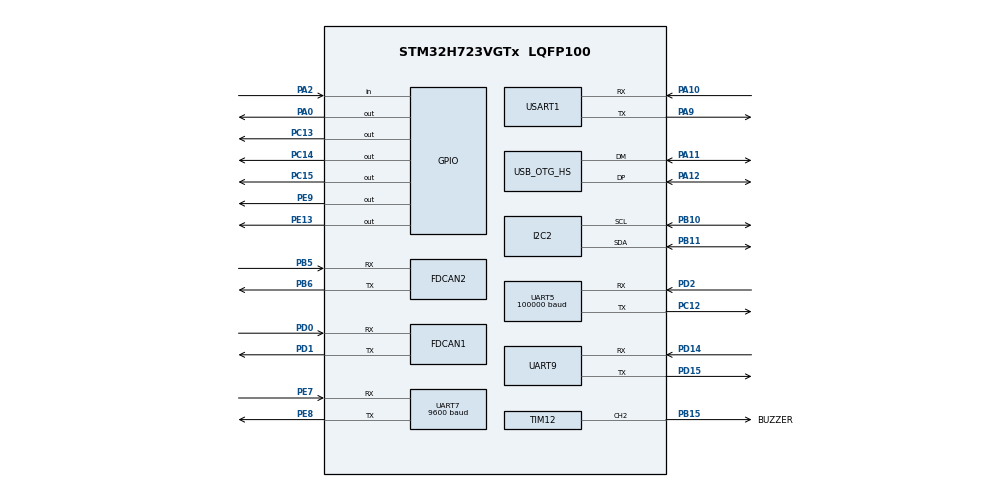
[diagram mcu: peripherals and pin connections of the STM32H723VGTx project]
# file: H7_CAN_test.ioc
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CORTEX_M7.default_mode_Activation=1
Dma.I2C2_RX.2.Direction=DMA_PERIPH_TO_MEMORY
Dma.I2C2_RX.2.EventEnable=DISABLE
Dma.I2C2_RX.2.FIFOMode=DMA_FIFOMODE_DISABLE
Dma.I2C2_RX.2.Instance=DMA1_Stream2
Dma.I2C2_RX.2.MemDataAlignment=DMA_MDATAALIGN_BYTE
Dma.I2C2_RX.2.MemInc=DMA_MINC_ENABLE
Dma.I2C2_RX.2.Mode=DMA_NORMAL
Dma.I2C2_RX.2.PeriphDataAlignment=DMA_PDATAALIGN_BYTE
Dma.I2C2_RX.2.PeriphInc=DMA_PINC_DISABLE
Dma.I2C2_RX.2.Polarity=HAL_DMAMUX_REQ_GEN_RISING
Dma.I2C2_RX.2.Priority=DMA_PRIORITY_LOW
Dma.I2C2_RX.2.RequestNumber=1
Dma.I2C2_RX.2.SignalID=NONE
Dma.I2C2_RX.2.SyncEnable=DISABLE
Dma.I2C2_RX.2.SyncPolarity=HAL_DMAMUX_SYNC_NO_EVENT
Dma.I2C2_RX.2.SyncRequestNumber=1
Dma.I2C2_RX.2.SyncSignalID=NONE
Dma.I2C2_TX.1.Direction=DMA_MEMORY_TO_PERIPH
Dma.I2C2_TX.1.EventEnable=DISABLE
Dma.I2C2_TX.1.FIFOMode=DMA_FIFOMODE_DISABLE
Dma.I2C2_TX.1.Instance=DMA1_Stream1
Dma.I2C2_TX.1.MemDataAlignment=DMA_MDATAALIGN_BYTE
Dma.I2C2_TX.1.MemInc=DMA_MINC_ENABLE
Dma.I2C2_TX.1.Mode=DMA_NORMAL
Dma.I2C2_TX.1.PeriphDataAlignment=DMA_PDATAALIGN_BYTE
Dma.I2C2_TX.1.PeriphInc=DMA_PINC_DISABLE
Dma.I2C2_TX.1.Polarity=HAL_DMAMUX_REQ_GEN_RISING
Dma.I2C2_TX.1.Priority=DMA_PRIORITY_LOW
Dma.I2C2_TX.1.RequestNumber=1
Dma.I2C2_TX.1.SignalID=NONE
Dma.I2C2_TX.1.SyncEnable=DISABLE
Dma.I2C2_TX.1.SyncPolarity=HAL_DMAMUX_SYNC_NO_EVENT
Dma.I2C2_TX.1.SyncRequestNumber=1
Dma.I2C2_TX.1.SyncSignalID=NONE
Dma.Request0=UART5_RX
Dma.Request1=I2C2_TX
Dma.Request2=I2C2_RX
Dma.UART5_RX.0.Direction=DMA_PERIPH_TO_MEMORY
Dma.UART5_RX.0.EventEnable=DISABLE
Dma.UART5_RX.0.FIFOMode=DMA_FIFOMODE_DISABLE
Dma.UART5_RX.0.Instance=DMA1_Stream0
Dma.UART5_RX.0.MemDataAlignment=DMA_MDATAALIGN_BYTE
Dma.UART5_RX.0.MemInc=DMA_MINC_ENABLE
Dma.UART5_RX.0.Mode=DMA_CIRCULAR
Dma.UART5_RX.0.PeriphDataAlignment=DMA_PDATAALIGN_BYTE
Dma.UART5_RX.0.PeriphInc=DMA_PINC_DISABLE
Dma.UART5_RX.0.Polarity=HAL_DMAMUX_REQ_GEN_RISING
Dma.UART5_RX.0.Priority=DMA_PRIORITY_LOW
Dma.UART5_RX.0.RequestNumber=1
Dma.UART5_RX.0.SignalID=NONE
Dma.UART5_RX.0.SyncEnable=DISABLE
Dma.UART5_RX.0.SyncPolarity=HAL_DMAMUX_SYNC_NO_EVENT
Dma.UART5_RX.0.SyncRequestNumber=1
Dma.UART5_RX.0.SyncSignalID=NONE
FDCAN1.CalculateBaudRateNominal=1000000
FDCAN1.CalculateTimeBitNominal=1000
FDCAN1.CalculateTimeQuantumNominal=25.0
FDCAN1.DataPrescaler=3
FDCAN1.DataSyncJumpWidth=10
FDCAN1.DataTimeSeg1=29
FDCAN1.DataTimeSeg2=10
FDCAN1.NominalPrescaler=3
FDCAN1.NominalSyncJumpWidth=10
FDCAN1.NominalTimeSeg1=29
FDCAN1.NominalTimeSeg2=10
FDCAN1.RxFifo0ElmtsNbr=2
FDCAN1.StdFiltersNbr=0x00000000
FDCAN1.TxFifoQueueElmtsNbr=2
FDCAN2.CalculateBaudRateNominal=1000000
FDCAN2.CalculateTimeBitNominal=1000
FDCAN2.CalculateTimeQuantumNominal=25.0
FDCAN2.DataPrescaler=3
FDCAN2.DataSyncJumpWidth=10
FDCAN2.DataTimeSeg1=29
FDCAN2.DataTimeSeg2=10
FDCAN2.NominalPrescaler=3
FDCAN2.NominalSyncJumpWidth=10
FDCAN2.NominalTimeSeg1=29
FDCAN2.NominalTimeSeg2=10
FDCAN2.RxFifo0ElmtsNbr=2
FDCAN2.StdFiltersNbr=0x00000000
FDCAN2.TxFifoQueueElmtsNbr=2
FREERTOS.Tasks01=defaultTask,0,128,StartDefaultTask,As weak,NULL,Dynamic,NULL,NULL;Classic_Task,0,128,Classic_Move,As weak,NULL,Dynamic,NULL,NULL;Chat_Task,0,128,Chat_with_upper,As weak,NULL,Dynamic,NULL,NULL;shout_ballTask,0,128,Shout_Ball,As weak,NULL,Dynamic,NULL,NULL;ChangeAngleTask,0,128,Chang_Shout_Angle,As weak,NULL,Dynamic,NULL,NULL;myTask06,0,128,Task_Changes,As weak,NULL,Dynamic,NULL,NULL
I2C2.Timing=0x307075B1
Mcu.Family=STM32H7
Mcu.Name=STM32H723VGTx
Mcu.Package=LQFP100
NVIC.DMA1_Stream0_IRQn=true\:5\:0\:false\:false\:true\:true\:false\:true\:true
NVIC.DMA1_Stream1_IRQn=true\:5\:0\:false\:false\:true\:true\:false\:true\:true
NVIC.DMA1_Stream2_IRQn=true\:5\:0\:false\:false\:true\:true\:false\:true\:true
NVIC.FDCAN1_IT0_IRQn=true\:0\:0\:true\:false\:true\:false\:true\:true\:true
NVIC.FDCAN2_IT0_IRQn=true\:0\:0\:true\:false\:true\:false\:true\:true\:true
NVIC.I2C2_EV_IRQn=true\:5\:0\:false\:false\:true\:false\:true\:true\:true
NVIC.OTG_HS_IRQn=true\:5\:0\:false\:false\:true\:true\:true\:true\:true
NVIC.PriorityGroup=NVIC_PRIORITYGROUP_4
NVIC.TIM7_IRQn=true\:5\:0\:false\:false\:true\:false\:true\:true\:true
NVIC.UART5_IRQn=true\:0\:0\:true\:false\:true\:false\:true\:true\:true
NVIC.UART7_IRQn=true\:0\:0\:true\:false\:true\:false\:true\:true\:true
NVIC.UART9_IRQn=true\:5\:0\:false\:false\:true\:false\:true\:true\:true
NVIC.USART1_IRQn=true\:5\:0\:false\:false\:true\:false\:true\:true\:true
PA0.Signal=GPIO_Output
PA10.Mode=Asynchronous
PA10.Signal=USART1_RX
PA11.Mode=Device_Only_FS
PA11.Signal=USB_OTG_HS_DM
PA12.Mode=Device_Only_FS
PA12.Signal=USB_OTG_HS_DP
PA13(JTMS/SWDIO).Mode=Serial_Wire
PA13(JTMS/SWDIO).Signal=DEBUG_JTMS-SWDIO
PA14(JTCK/SWCLK).Mode=Serial_Wire
PA14(JTCK/SWCLK).Signal=DEBUG_JTCK-SWCLK
PA2.GPIO_PuPd=GPIO_PULLUP
PA2.Signal=GPIO_Input
PA9.Mode=Asynchronous
PA9.Signal=USART1_TX
PB10.Mode=I2C
PB10.Signal=I2C2_SCL
PB11.Mode=I2C
PB11.Signal=I2C2_SDA
PB15.GPIO_Label=BUZZER
PB15.GPIO_Speed=GPIO_SPEED_FREQ_HIGH
PB15.Signal=S_TIM12_CH2
PB5.Mode=FDCAN_Activate
PB5.Signal=FDCAN2_RX
PB6.Mode=FDCAN_Activate
PB6.Signal=FDCAN2_TX
PC12.Mode=Asynchronous
PC12.Signal=UART5_TX
PC13.PinState=GPIO_PIN_SET
PC13.Signal=GPIO_Output
PC14-OSC32_IN.PinState=GPIO_PIN_SET
PC14-OSC32_IN.Signal=GPIO_Output
PC15-OSC32_OUT.PinState=GPIO_PIN_SET
PC15-OSC32_OUT.Signal=GPIO_Output
PD0.Mode=FDCAN_Activate
PD0.Signal=FDCAN1_RX
PD1.Mode=FDCAN_Activate
PD1.Signal=FDCAN1_TX
PD14.Mode=Asynchronous
PD14.Signal=UART9_RX
PD15.Mode=Asynchronous
PD15.Signal=UART9_TX
PD2.Mode=Asynchronous
PD2.Signal=UART5_RX
PE13.Signal=GPIO_Output
PE7.Mode=Asynchronous
PE7.Signal=UART7_RX
PE8.Mode=Asynchronous
PE8.Signal=UART7_TX
PE9.Signal=GPIO_Output
PH0-OSC_IN.Mode=HSE-External-Oscillator
PH0-OSC_IN.Signal=RCC_OSC_IN
PH1-OSC_OUT.Mode=HSE-External-Oscillator
PH1-OSC_OUT.Signal=RCC_OSC_OUT
ProjectManager.HeapSize=0x200
ProjectManager.StackSize=0x400
ProjectManager.TargetToolchain=MDK-ARM V5.32
RCC.ADCFreq_Value=48375000
RCC.APB1Freq_Value=120000000
RCC.APB2Freq_Value=120000000
RCC.APB3Freq_Value=120000000
RCC.APB4Freq_Value=120000000
RCC.CortexFreq_Value=480000000
RCC.D1PPRE=RCC_APB3_DIV2
RCC.D2PPRE1=RCC_APB1_DIV2
RCC.D2PPRE2=RCC_APB2_DIV2
RCC.D3PPRE=RCC_APB4_DIV2
RCC.DIVM1=2
RCC.DIVM3=2
RCC.DIVN1=40
RCC.DIVN3=16
RCC.DIVP1=1
RCC.DIVQ1=4
RCC.DIVQ3=4
RCC.HCLKFreq_Value=240000000
RCC.HPRE=RCC_HCLK_DIV2
RCC.HSE_VALUE=24000000
RCC.PLL3FRACN=0
RCC.PLLFRACN=0
RCC.PLLSourceVirtual=RCC_PLLSOURCE_HSE
RCC.SYSCLKFreq_VALUE=480000000
RCC.SYSCLKSource=RCC_SYSCLKSOURCE_PLLCLK
RCC.USBCLockSelection=RCC_USBCLKSOURCE_PLL3
RCC.USBFreq_Value=48000000
SH.S_TIM12_CH2.0=TIM12_CH2,PWM Generation2 CH2
TIM12.Channel-PWM\ Generation2\ CH2=TIM_CHANNEL_2
TIM12.Period=2500-1
TIM12.Prescaler=24-1
TIM7.Period=100-1
TIM7.Prescaler=24000-1
UART5.BaudRate=100000
UART5.Mode=MODE_RX
UART5.WordLength=WORDLENGTH_9B
UART7.BaudRate=9600
USART1.VirtualMode-Asynchronous=VM_ASYNC
USB_DEVICE.CLASS_NAME_HS=CDC
USB_DEVICE.VirtualMode=Cdc
USB_DEVICE.VirtualModeHS=Cdc_HS
USB_OTG_HS.VirtualMode-Device_Only_FS=Device_Only_FS
VP_FREERTOS_VS_CMSIS_V1.Mode=CMSIS_V1
VP_MEMORYMAP_VS_MEMORYMAP.Mode=CurAppReg
VP_TIM7_VS_ClockSourceINT.Mode=Enable_Timer
VP_USB_DEVICE_VS_USB_DEVICE_CDC_HS.Mode=CDC_HS
board=custom

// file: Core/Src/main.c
/* USER CODE BEGIN Header */
/**
  ******************************************************************************
  * @file           : main.c
  * @brief          : Main program body
  ******************************************************************************
  * @attention
  *
  * Copyright (c) 2025 STMicroelectronics.
  * All rights reserved.
  *
  * This software is licensed under terms that can be found in the LICENSE file
  * in the root directory of this software component.
  * If no LICENSE file comes with this software, it is provided AS-IS.
  *
  ******************************************************************************
  */
/* USER CODE END Header */
#include "main.h"
#include "cmsis_os.h"
#include "dma.h"
#include "fdcan.h"
#include "i2c.h"
#include "memorymap.h"
#include "tim.h"
#include "usart.h"
#include "usb_device.h"
#include "gpio.h"

/* USER CODE BEGIN Includes */
#include "startup_main.h"
/* USER CODE END Includes */

void SystemClock_Config(void);
static void MPU_Config(void);
void MX_FREERTOS_Init(void);

int main(void)
{

  /* MPU Configuration--------------------------------------------------------*/
  MPU_Config();

  /* MCU Configuration--------------------------------------------------------*/

  /* Reset of all peripherals, Initializes the Flash interface and the Systick. */
  HAL_Init();

  /* Configure the system clock */
  SystemClock_Config();

  /* Initialize all configured peripherals */
  MX_GPIO_Init();
  MX_DMA_Init();
  MX_FDCAN1_Init();
  MX_FDCAN2_Init();
  MX_TIM7_Init();
  MX_UART7_Init();
  MX_UART5_Init();
  MX_USART1_UART_Init();
  MX_I2C2_Init();
  MX_UART9_Init();
  MX_TIM12_Init();
  /* USER CODE BEGIN 2 */
  startup_main();
  /* USER CODE END 2 */

  /* Call init function for freertos objects (in cmsis_os2.c) */
  MX_FREERTOS_Init();

  /* Start scheduler */
  osKernelStart();

  /* We should never get here as control is now taken by the scheduler */

  /* Infinite loop */
  while (1)
  {

  }
}

void SystemClock_Config(void)
{
  RCC_OscInitTypeDef RCC_OscInitStruct = {0};
  RCC_ClkInitTypeDef RCC_ClkInitStruct = {0};

  /** Supply configuration update enable
  */
  HAL_PWREx_ConfigSupply(PWR_LDO_SUPPLY);

  /** Configure the main internal regulator output voltage
  */
  __HAL_PWR_VOLTAGESCALING_CONFIG(PWR_REGULATOR_VOLTAGE_SCALE0);

  while(!__HAL_PWR_GET_FLAG(PWR_FLAG_VOSRDY)) {}

  /** Initializes the RCC Oscillators according to the specified parameters
  * in the RCC_OscInitTypeDef structure.
  */
  RCC_OscInitStruct.OscillatorType = RCC_OSCILLATORTYPE_HSE;
  RCC_OscInitStruct.HSEState = RCC_HSE_ON;
  RCC_OscInitStruct.PLL.PLLState = RCC_PLL_ON;
  RCC_OscInitStruct.PLL.PLLSource = RCC_PLLSOURCE_HSE;
  RCC_OscInitStruct.PLL.PLLM = 2;
  RCC_OscInitStruct.PLL.PLLN = 40;
  RCC_OscInitStruct.PLL.PLLP = 1;
  RCC_OscInitStruct.PLL.PLLQ = 4;
  RCC_OscInitStruct.PLL.PLLR = 2;
  RCC_OscInitStruct.PLL.PLLRGE = RCC_PLL1VCIRANGE_3;
  RCC_OscInitStruct.PLL.PLLVCOSEL = RCC_PLL1VCOWIDE;
  RCC_OscInitStruct.PLL.PLLFRACN = 0;
  if (HAL_RCC_OscConfig(&RCC_OscInitStruct) != HAL_OK)
  {
    Error_Handler();
  }

  /** Initializes the CPU, AHB and APB buses clocks
  */
  RCC_ClkInitStruct.ClockType = RCC_CLOCKTYPE_HCLK|RCC_CLOCKTYPE_SYSCLK
                              |RCC_CLOCKTYPE_PCLK1|RCC_CLOCKTYPE_PCLK2
                              |RCC_CLOCKTYPE_D3PCLK1|RCC_CLOCKTYPE_D1PCLK1;
  RCC_ClkInitStruct.SYSCLKSource = RCC_SYSCLKSOURCE_PLLCLK;
  RCC_ClkInitStruct.SYSCLKDivider = RCC_SYSCLK_DIV1;
  RCC_ClkInitStruct.AHBCLKDivider = RCC_HCLK_DIV2;
  RCC_ClkInitStruct.APB3CLKDivider = RCC_APB3_DIV2;
  RCC_ClkInitStruct.APB1CLKDivider = RCC_APB1_DIV2;
  RCC_ClkInitStruct.APB2CLKDivider = RCC_APB2_DIV2;
  RCC_ClkInitStruct.APB4CLKDivider = RCC_APB4_DIV2;

  if (HAL_RCC_ClockConfig(&RCC_ClkInitStruct, FLASH_LATENCY_3) != HAL_OK)
  {
    Error_Handler();
  }
}

 /* MPU Configuration */

void MPU_Config(void)
{
  MPU_Region_InitTypeDef MPU_InitStruct = {0};

  /* Disables the MPU */
  HAL_MPU_Disable();

  /** Initializes and configures the Region and the memory to be protected
  */
  MPU_InitStruct.Enable = MPU_REGION_ENABLE;
  MPU_InitStruct.Number = MPU_REGION_NUMBER0;
  MPU_InitStruct.BaseAddress = 0x0;
  MPU_InitStruct.Size = MPU_REGION_SIZE_4GB;
  MPU_InitStruct.SubRegionDisable = 0x87;
  MPU_InitStruct.TypeExtField = MPU_TEX_LEVEL0;
  MPU_InitStruct.AccessPermission = MPU_REGION_NO_ACCESS;
  MPU_InitStruct.DisableExec = MPU_INSTRUCTION_ACCESS_DISABLE;
  MPU_InitStruct.IsShareable = MPU_ACCESS_SHAREABLE;
  MPU_InitStruct.IsCacheable = MPU_ACCESS_NOT_CACHEABLE;
  MPU_InitStruct.IsBufferable = MPU_ACCESS_NOT_BUFFERABLE;

  HAL_MPU_ConfigRegion(&MPU_InitStruct);
  /* Enables the MPU */
  HAL_MPU_Enable(MPU_PRIVILEGED_DEFAULT);

}

void Error_Handler(void)
{
  __disable_irq();
  while (1)
  {
  }
}

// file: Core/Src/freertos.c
/* USER CODE BEGIN Header */
/**
  ******************************************************************************
  * File Name          : freertos.c
  * Description        : Code for freertos applications
  ******************************************************************************
  * @attention
  *
  * Copyright (c) 2025 STMicroelectronics.
  * All rights reserved.
  *
  * This software is licensed under terms that can be found in the LICENSE file
  * in the root directory of this software component.
  * If no LICENSE file comes with this software, it is provided AS-IS.
  *
  ******************************************************************************
  */
/* USER CODE END Header */

#include "FreeRTOS.h"
#include "task.h"
#include "main.h"
#include "cmsis_os.h"

/* USER CODE BEGIN Variables */
// osThreadId StartLaunchTaskHandle;
/* USER CODE END Variables */
osThreadId defaultTaskHandle;
osThreadId Classic_TaskHandle;
osThreadId Chat_TaskHandle;
osThreadId shout_ballTaskHandle;
osThreadId ChangeAngleTaskHandle;
osThreadId myTask06Handle;

/* USER CODE BEGIN FunctionPrototypes */
// void StartLaunchTask(void const * argument);
/* USER CODE END FunctionPrototypes */

void StartDefaultTask(void const * argument);
void Classic_Move(void const * argument);
void Chat_with_upper(void const * argument);
void Shout_Ball(void const * argument);
void Chang_Shout_Angle(void const * argument);
void Task_Changes(void const * argument);

extern void MX_USB_DEVICE_Init(void);
void MX_FREERTOS_Init(void); /* (MISRA C 2004 rule 8.1) */

/* GetIdleTaskMemory prototype (linked to static allocation support) */
void vApplicationGetIdleTaskMemory( StaticTask_t **ppxIdleTaskTCBBuffer, StackType_t **ppxIdleTaskStackBuffer, uint32_t *pulIdleTaskStackSize );

/* USER CODE BEGIN GET_IDLE_TASK_MEMORY */
static StaticTask_t xIdleTaskTCBBuffer;
static StackType_t xIdleStack[configMINIMAL_STACK_SIZE];

void vApplicationGetIdleTaskMemory( StaticTask_t **ppxIdleTaskTCBBuffer, StackType_t **ppxIdleTaskStackBuffer, uint32_t *pulIdleTaskStackSize )
{
  *ppxIdleTaskTCBBuffer = &xIdleTaskTCBBuffer;
  *ppxIdleTaskStackBuffer = &xIdleStack[0];
  *pulIdleTaskStackSize = configMINIMAL_STACK_SIZE;
  /* place for user code */
}
/* USER CODE END GET_IDLE_TASK_MEMORY */

void MX_FREERTOS_Init(void) {

  /* Create the thread(s) */
  /* definition and creation of defaultTask */
  osThreadDef(defaultTask, StartDefaultTask, osPriorityNormal, 0, 128);
  defaultTaskHandle = osThreadCreate(osThread(defaultTask), NULL);

  /* definition and creation of Classic_Task */
  osThreadDef(Classic_Task, Classic_Move, osPriorityNormal, 0, 128);
  Classic_TaskHandle = osThreadCreate(osThread(Classic_Task), NULL);

  /* definition and creation of Chat_Task */
  osThreadDef(Chat_Task, Chat_with_upper, osPriorityNormal, 0, 128);
  Chat_TaskHandle = osThreadCreate(osThread(Chat_Task), NULL);

  /* definition and creation of shout_ballTask */
  osThreadDef(shout_ballTask, Shout_Ball, osPriorityNormal, 0, 128);
  shout_ballTaskHandle = osThreadCreate(osThread(shout_ballTask), NULL);

  /* definition and creation of ChangeAngleTask */
  osThreadDef(ChangeAngleTask, Chang_Shout_Angle, osPriorityNormal, 0, 128);
  ChangeAngleTaskHandle = osThreadCreate(osThread(ChangeAngleTask), NULL);

  /* definition and creation of myTask06 */
  osThreadDef(myTask06, Task_Changes, osPriorityNormal, 0, 128);
  myTask06Handle = osThreadCreate(osThread(myTask06), NULL);

  /* USER CODE BEGIN RTOS_THREADS */
  /* add threads, ... */
  // osThreadDef(LaunchTask, StartLaunchTask, osPriorityNormal, 0, 128);  // ע������
  /* USER CODE END RTOS_THREADS */

}

__weak void StartDefaultTask(void const * argument)
{
  /* init code for USB_DEVICE */
  MX_USB_DEVICE_Init();
  for(;;)
  {
    osDelay(1);
  }
}

__weak void Classic_Move(void const * argument)
{
  for(;;)
  {
    osDelay(1);
  }
}

__weak void Chat_with_upper(void const * argument)
{
  for(;;)
  {
    osDelay(1);
  }
}

__weak void Shout_Ball(void const * argument)
{
  for(;;)
  {
    osDelay(1);
  }
}

__weak void Chang_Shout_Angle(void const * argument)
{
  for(;;)
  {
    osDelay(1);
  }
}

__weak void Task_Changes(void const * argument)
{
  for(;;)
  {
    osDelay(1);
  }
}

/* USER CODE BEGIN Application */
// __weak void StartLaunchTask(void const * argument)
// {

// }
/* USER CODE END Application */
